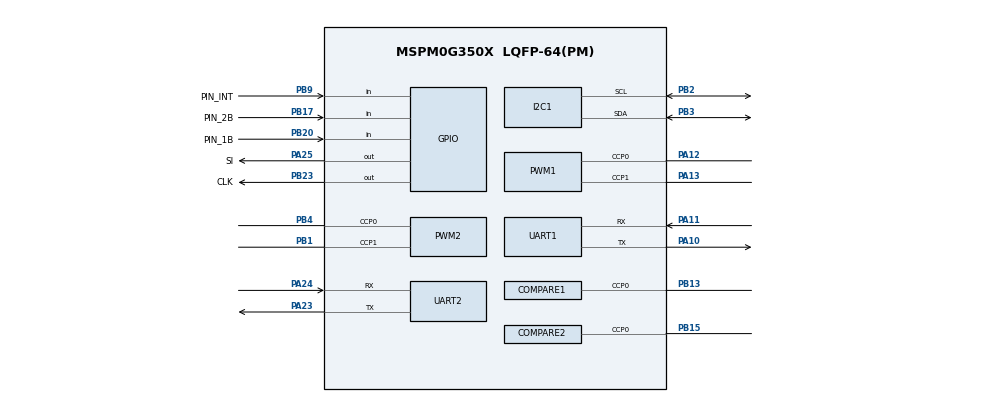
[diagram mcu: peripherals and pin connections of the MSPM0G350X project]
/**
 * @cliArgs --device "MSPM0G350X" --part "Default" --package "LQFP-64(PM)" --product "mspm0_sdk@2.05.01.00"
 * @versions {"tool":"1.24.0+4110"}
 */

/**
 * Import the modules used in this configuration.
 */
const ADC12         = scripting.addModule("/ti/driverlib/ADC12", {}, false);
const ADC121        = ADC12.addInstance();
const COMPARE       = scripting.addModule("/ti/driverlib/COMPARE", {}, false);
const COMPARE1      = COMPARE.addInstance();
const COMPARE2      = COMPARE.addInstance();
const GPIO          = scripting.addModule("/ti/driverlib/GPIO", {}, false);
const GPIO1         = GPIO.addInstance();
const GPIO2         = GPIO.addInstance();
const GPIO3         = GPIO.addInstance();
const GPIO4         = GPIO.addInstance();
const I2C           = scripting.addModule("/ti/driverlib/I2C", {}, false);
const I2C1          = I2C.addInstance();
const PWM           = scripting.addModule("/ti/driverlib/PWM", {}, false);
const PWM1          = PWM.addInstance();
const PWM2          = PWM.addInstance();
const SYSCTL        = scripting.addModule("/ti/driverlib/SYSCTL");
const TIMER         = scripting.addModule("/ti/driverlib/TIMER", {}, false);
const TIMER1        = TIMER.addInstance();
const UART          = scripting.addModule("/ti/driverlib/UART", {}, false);
const UART1         = UART.addInstance();
const UART2         = UART.addInstance();
const ProjectConfig = scripting.addModule("/ti/project_config/ProjectConfig");

/**
 * Write custom configuration values to the imported modules.
 */
ADC121.$name                      = "ADC12_0";
ADC121.sampClkDiv                 = "DL_ADC12_CLOCK_DIVIDE_4";
ADC121.sampCnt                    = 1;
ADC121.enabledDMATriggers         = ["DL_ADC12_DMA_MEM0_RESULT_LOADED"];
ADC121.powerDownMode              = "DL_ADC12_POWER_DOWN_MODE_MANUAL";
ADC121.sampleTime0                = "1us";
ADC121.interruptPriority          = "0";
ADC121.peripheral.$assign         = "ADC0";
ADC121.peripheral.adcPin0.$assign = "PA27";
ADC121.adcPin0Config.$name        = "ti_driverlib_gpio_GPIOPinGeneric0";

const Board = scripting.addModule("/ti/driverlib/Board", {}, false);

COMPARE1.$name                      = "COMPARE_0";
COMPARE1.filteringMode              = "VOTING";
COMPARE1.compareMode                = "EDGE_COUNT_UP";
COMPARE1.interrupts                 = ["LOAD"];
COMPARE1.timerPeriod                = 10;
COMPARE1.peripheral.ccp0Pin.$assign = "PB13";
COMPARE1.ccp0PinConfig.$name        = "ti_driverlib_gpio_GPIOPinGeneric5";

COMPARE2.$name                      = "COMPARE_1";
COMPARE2.compareMode                = "EDGE_COUNT_UP";
COMPARE2.interrupts                 = ["LOAD"];
COMPARE2.timerPeriod                = 10;
COMPARE2.peripheral.ccp0Pin.$assign = "PB15";
COMPARE2.ccp0PinConfig.$name        = "ti_driverlib_gpio_GPIOPinGeneric6";

GPIO1.$name                          = "GPIO_DC";
GPIO1.associatedPins.create(2);
GPIO1.associatedPins[0].assignedPort = "PORTB";
GPIO1.associatedPins[0].assignedPin  = "8";
GPIO1.associatedPins[0].interruptEn  = true;
GPIO1.associatedPins[0].$name        = "AIN0";
GPIO1.associatedPins[1].assignedPort = "PORTB";
GPIO1.associatedPins[1].assignedPin  = "6";
GPIO1.associatedPins[1].polarity     = "RISE_FALL";
GPIO1.associatedPins[1].$name        = "AIN2";

GPIO2.$name                               = "GPIO_ENCODER";
GPIO2.port                                = "PORTB";
GPIO2.associatedPins.create(2);
GPIO2.associatedPins[0].$name             = "PIN_1B";
GPIO2.associatedPins[0].direction         = "INPUT";
GPIO2.associatedPins[0].inputFilter       = "8_CYCLES";
GPIO2.associatedPins[0].polarity          = "RISE";
GPIO2.associatedPins[0].internalResistor  = "PULL_UP";
GPIO2.associatedPins[0].ioStructure       = "SD";
GPIO2.associatedPins[0].pin.$assign       = "PB20";
GPIO2.associatedPins[1].$name             = "PIN_2B";
GPIO2.associatedPins[1].direction         = "INPUT";
GPIO2.associatedPins[1].ioStructure       = "SD";
GPIO2.associatedPins[1].inputFilter       = "8_CYCLES";
GPIO2.associatedPins[1].polarity          = "RISE";
GPIO2.associatedPins[1].internalResistor  = "PULL_UP";
GPIO2.associatedPins[1].interruptPriority = "1";
GPIO2.associatedPins[1].pin.$assign       = "PB17";

GPIO3.$name                         = "GPIO_CCD";
GPIO3.associatedPins.create(2);
GPIO3.associatedPins[0].$name       = "SI";
GPIO3.associatedPins[0].pin.$assign = "PA25";
GPIO3.associatedPins[1].$name       = "CLK";
GPIO3.associatedPins[1].pin.$assign = "PB23";

GPIO4.$name                               = "GPIO_LSM6DSV16X";
GPIO4.associatedPins[0].direction         = "INPUT";
GPIO4.associatedPins[0].interruptEn       = true;
GPIO4.associatedPins[0].polarity          = "RISE";
GPIO4.associatedPins[0].interruptPriority = "3";
GPIO4.associatedPins[0].$name             = "PIN_INT";
GPIO4.associatedPins[0].pin.$assign       = "PB9";

I2C1.$name                             = "I2C_LSM6DSV16X";
I2C1.basicEnableController             = true;
I2C1.basicControllerStandardBusSpeed   = "Fast";
I2C1.peripheral.$assign                = "I2C1";
I2C1.peripheral.sdaPin.$assign         = "PB3";
I2C1.peripheral.sclPin.$assign         = "PB2";
I2C1.sdaPinConfig.hideOutputInversion  = scripting.forceWrite(false);
I2C1.sdaPinConfig.onlyInternalResistor = scripting.forceWrite(false);
I2C1.sdaPinConfig.passedPeripheralType = scripting.forceWrite("Digital");
I2C1.sdaPinConfig.$name                = "ti_driverlib_gpio_GPIOPinGeneric11";
I2C1.sclPinConfig.hideOutputInversion  = scripting.forceWrite(false);
I2C1.sclPinConfig.onlyInternalResistor = scripting.forceWrite(false);
I2C1.sclPinConfig.passedPeripheralType = scripting.forceWrite("Digital");
I2C1.sclPinConfig.$name                = "ti_driverlib_gpio_GPIOPinGeneric12";

PWM1.$name                              = "PWM_DC";
PWM1.timerCount                         = 10000;
PWM1.clockDivider                       = 4;
PWM1.clockPrescale                      = 8;
PWM1.peripheral.$assign                 = "TIMG0";
PWM1.peripheral.ccp0Pin.$assign         = "PA12";
PWM1.peripheral.ccp1Pin.$assign         = "PA13";
PWM1.PWM_CHANNEL_0.$name                = "ti_driverlib_pwm_PWMTimerCC0";
PWM1.PWM_CHANNEL_0.dutyCycle            = 2;
PWM1.PWM_CHANNEL_1.$name                = "ti_driverlib_pwm_PWMTimerCC1";
PWM1.PWM_CHANNEL_1.dutyCycle            = 2;
PWM1.ccp0PinConfig.direction            = scripting.forceWrite("OUTPUT");
PWM1.ccp0PinConfig.hideOutputInversion  = scripting.forceWrite(false);
PWM1.ccp0PinConfig.onlyInternalResistor = scripting.forceWrite(false);
PWM1.ccp0PinConfig.passedPeripheralType = scripting.forceWrite("Digital");
PWM1.ccp0PinConfig.$name                = "ti_driverlib_gpio_GPIOPinGeneric1";
PWM1.ccp1PinConfig.direction            = scripting.forceWrite("OUTPUT");
PWM1.ccp1PinConfig.hideOutputInversion  = scripting.forceWrite(false);
PWM1.ccp1PinConfig.onlyInternalResistor = scripting.forceWrite(false);
PWM1.ccp1PinConfig.passedPeripheralType = scripting.forceWrite("Digital");
PWM1.ccp1PinConfig.$name                = "ti_driverlib_gpio_GPIOPinGeneric2";

PWM2.$name                              = "PWM_PTZ";
PWM2.clockDivider                       = 8;
PWM2.timerCount                         = 10000;
PWM2.clockPrescale                      = 8;
PWM2.pwmMode                            = "EDGE_ALIGN_UP";
PWM2.peripheral.ccp0Pin.$assign         = "PB4";
PWM2.peripheral.ccp1Pin.$assign         = "PB1";
PWM2.PWM_CHANNEL_0.$name                = "ti_driverlib_pwm_PWMTimerCC2";
PWM2.PWM_CHANNEL_0.dutyCycle            = 7.5;
PWM2.PWM_CHANNEL_1.$name                = "ti_driverlib_pwm_PWMTimerCC3";
PWM2.PWM_CHANNEL_1.dutyCycle            = 7.5;
PWM2.ccp0PinConfig.$name                = "ti_driverlib_gpio_GPIOPinGeneric7";
PWM2.ccp0PinConfig.direction            = scripting.forceWrite("OUTPUT");
PWM2.ccp0PinConfig.hideOutputInversion  = scripting.forceWrite(false);
PWM2.ccp0PinConfig.onlyInternalResistor = scripting.forceWrite(false);
PWM2.ccp0PinConfig.passedPeripheralType = scripting.forceWrite("Digital");
PWM2.ccp1PinConfig.$name                = "ti_driverlib_gpio_GPIOPinGeneric8";
PWM2.ccp1PinConfig.direction            = scripting.forceWrite("OUTPUT");
PWM2.ccp1PinConfig.hideOutputInversion  = scripting.forceWrite(false);
PWM2.ccp1PinConfig.onlyInternalResistor = scripting.forceWrite(false);
PWM2.ccp1PinConfig.passedPeripheralType = scripting.forceWrite("Digital");

SYSCTL.forceDefaultClkConfig = true;

TIMER1.$name             = "TIMER_0";
TIMER1.timerClkDiv       = 8;
TIMER1.timerMode         = "PERIODIC";
TIMER1.interrupts        = ["ZERO"];
TIMER1.interruptPriority = "2";
TIMER1.timerPeriod       = "1 ms";

UART1.$name                            = "UART_SCREEN";
UART1.uartClkSrc                       = "LFCLK";
UART1.ovsRate                          = "3";
UART1.enabledInterrupts                = ["RX"];
UART1.peripheral.rxPin.$assign         = "PA11";
UART1.peripheral.txPin.$assign         = "PA10";
UART1.txPinConfig.direction            = scripting.forceWrite("OUTPUT");
UART1.txPinConfig.hideOutputInversion  = scripting.forceWrite(false);
UART1.txPinConfig.onlyInternalResistor = scripting.forceWrite(false);
UART1.txPinConfig.passedPeripheralType = scripting.forceWrite("Digital");
UART1.txPinConfig.$name                = "ti_driverlib_gpio_GPIOPinGeneric3";
UART1.rxPinConfig.hideOutputInversion  = scripting.forceWrite(false);
UART1.rxPinConfig.onlyInternalResistor = scripting.forceWrite(false);
UART1.rxPinConfig.passedPeripheralType = scripting.forceWrite("Digital");
UART1.rxPinConfig.$name                = "ti_driverlib_gpio_GPIOPinGeneric4";

UART2.targetBaudRate                   = 115200;
UART2.$name                            = "UART_K230";
UART2.enabledInterrupts                = ["RX"];
UART2.peripheral.$assign               = "UART2";
UART2.peripheral.rxPin.$assign         = "PA24";
UART2.peripheral.txPin.$assign         = "PA23";
UART2.txPinConfig.direction            = scripting.forceWrite("OUTPUT");
UART2.txPinConfig.hideOutputInversion  = scripting.forceWrite(false);
UART2.txPinConfig.onlyInternalResistor = scripting.forceWrite(false);
UART2.txPinConfig.passedPeripheralType = scripting.forceWrite("Digital");
UART2.txPinConfig.$name                = "ti_driverlib_gpio_GPIOPinGeneric9";
UART2.rxPinConfig.hideOutputInversion  = scripting.forceWrite(false);
UART2.rxPinConfig.onlyInternalResistor = scripting.forceWrite(false);
UART2.rxPinConfig.passedPeripheralType = scripting.forceWrite("Digital");
UART2.rxPinConfig.$name                = "ti_driverlib_gpio_GPIOPinGeneric10";

/**
 * Pinmux solution for unlocked pins/peripherals. This ensures that minor changes to the automatic solver in a future
 * version of the tool will not impact the pinmux you originally saw.  These lines can be completely deleted in order to
 * re-solve from scratch.
 */
Board.peripheral.$suggestSolution            = "DEBUGSS";
Board.peripheral.swclkPin.$suggestSolution   = "PA20";
Board.peripheral.swdioPin.$suggestSolution   = "PA19";
COMPARE1.peripheral.$suggestSolution         = "TIMG12";
COMPARE2.peripheral.$suggestSolution         = "TIMG7";
GPIO1.associatedPins[0].pin.$suggestSolution = "PB8";
GPIO1.associatedPins[1].pin.$suggestSolution = "PB6";
PWM2.peripheral.$suggestSolution             = "TIMA1";
SYSCTL.peripheral.$suggestSolution           = "SYSCTL";
TIMER1.peripheral.$suggestSolution           = "TIMA0";
UART1.peripheral.$suggestSolution            = "UART0";
